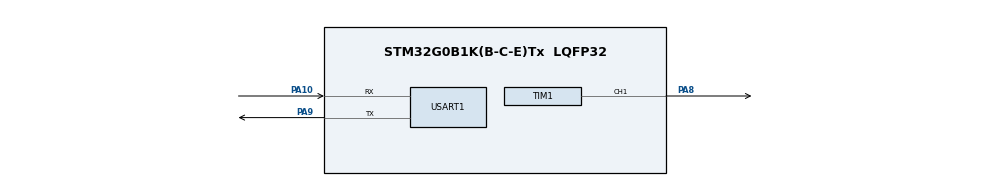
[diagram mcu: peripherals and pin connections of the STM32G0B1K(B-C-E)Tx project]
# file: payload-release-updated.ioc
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Mcu.Family=STM32G0
Mcu.Name=STM32G0B1K(B-C-E)Tx
Mcu.Package=LQFP32
PA10.Mode=Asynchronous
PA10.Signal=USART1_RX
PA8.Signal=S_TIM1_CH1
PA9.Mode=Asynchronous
PA9.Signal=USART1_TX
ProjectManager.HeapSize=0x200
ProjectManager.StackSize=0x400
ProjectManager.TargetToolchain=CMake
RCC.AHBFreq_Value=16000000
RCC.CortexFreq_Value=16000000
RCC.EXTERNAL_CLOCK_VALUE=48000
RCC.HCLKFreq_Value=16000000
RCC.HSE_VALUE=8000000
RCC.HSI48_VALUE=48000000
RCC.HSI_VALUE=16000000
RCC.LSE_VALUE=32768
RCC.SYSCLKFreq_VALUE=16000000
RCC.USBFreq_Value=48000000
RCC.VCOOutputFreq_Value=128000000
SH.S_TIM1_CH1.0=TIM1_CH1,PWM Generation1 CH1
TIM1.Channel-PWM\ Generation1\ CH1=TIM_CHANNEL_1
TIM1.Period=19999
TIM1.Prescaler=15
TIM1.Pulse-PWM\ Generation1\ CH1=1500
USART1.VirtualMode-Asynchronous=VM_ASYNC
VP_SYS_VS_DBSignals.Mode=DisableDeadBatterySignals
VP_TIM1_VS_ClockSourceINT.Mode=Internal
board=custom

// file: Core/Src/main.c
/* USER CODE BEGIN Header */
/**
  ******************************************************************************
  * @file           : main.c
  * @brief          : Main program body
  ******************************************************************************
  * @attention
  *
  * Copyright (c) 2026 STMicroelectronics.
  * All rights reserved.
  *
  * This software is licensed under terms that can be found in the LICENSE file
  * in the root directory of this software component.
  * If no LICENSE file comes with this software, it is provided AS-IS.
  *
  ******************************************************************************
  */
/* USER CODE END Header */
#include <stdint.h>
#include "system_stm32g0xx.h"
#define _GNU_SOURCE
#include "main.h"

/* USER CODE BEGIN Includes */
#include <stdint.h>
#include <stdbool.h>
#include <string.h>
#include <ctype.h>
#include "uart.h"
#include "servo_control.h"
#include <stdio.h>
/* USER CODE END Includes */

/* USER CODE BEGIN PTD */
typedef enum PayloadState {
  LOCKED,
  ARMED,
  RELEASING,
  RETRACTING,
  FAULT,
  INVALID
} PayloadState;
/* USER CODE END PTD */

/* USER CODE BEGIN PD */
#define RELEASE_MS 2000
#define RETRACT_MS 2000
/* USER CODE END PD */

/* USER CODE BEGIN PM */
#define MAX_CMD_LEN 4
/* USER CODE END PM */

/* USER CODE BEGIN PV */
static uint8_t character;
static uint8_t cmd[MAX_CMD_LEN];
static uint8_t idx;
static PayloadState state;
/* USER CODE END PV */

void SystemClock_Config(void);
static void MX_GPIO_Init(void);
static void MX_TIM1_Init(void);
static void MX_USART1_UART_Init(void);
/* USER CODE BEGIN PFP */
extern volatile uint32_t ticks_ms;
/* USER CODE END PFP */

/* USER CODE BEGIN 0 */
void SysTick_Init() {
  SysTick->CTRL = 0; // Disable SysTick
  SysTick->LOAD = (SystemCoreClock / 1000) - 1;  // Set reload for 1-second interval (at 16 MHz)
  SysTick->VAL  = 0; // Clear current value and flag
  // Enable counter, interrupt, and CPU clock
  SysTick->CTRL = SysTick_CTRL_ENABLE_Msk | SysTick_CTRL_TICKINT_Msk | SysTick_CTRL_CLKSOURCE_Msk;
}
/* USER CODE END 0 */

int main(void)
{
  /* USER CODE BEGIN 1 */
  long long rels_start_ms;
  long long retr_start_ms;
  long long rels_time;
  long long retr_time;
  bool rels_started = false;
  bool retr_started = false;
  bool rels_finished = false;
  bool retr_finished = false;
  bool char_ready = false;
  /* USER CODE END 1 */

  /* MCU Configuration--------------------------------------------------------*/

  /* Reset of all peripherals, Initializes the Flash interface and the Systick. */
  LL_APB2_GRP1_EnableClock(LL_APB2_GRP1_PERIPH_SYSCFG);
  LL_APB1_GRP1_EnableClock(LL_APB1_GRP1_PERIPH_PWR);

  /* SysTick_IRQn interrupt configuration */
  NVIC_SetPriority(SysTick_IRQn, 3);

  /** Disable the internal Pull-Up in Dead Battery pins of UCPD peripheral
  */
  LL_SYSCFG_DisableDBATT(LL_SYSCFG_UCPD1_STROBE);

  /* Configure the system clock */
  SystemClock_Config();

  /* USER CODE BEGIN SysInit */
  SysTick_Init();
  /* USER CODE END SysInit */

  /* Initialize all configured peripherals */
  MX_GPIO_Init();
  MX_TIM1_Init();
  MX_USART1_UART_Init();

  /* Infinite loop */
  /* USER CODE BEGIN WHILE */
  while (1)
  {
    // read uart input character
    // if valid character add it to cmd array
    // check if character array is a valid command
    // execute the command via dispatch table
    char_ready = read_character(&character);
    if (char_ready) {
		if (!isalpha(character) || character == 0) {
			char msg[128];
			snprintf(msg, sizeof(msg), "ERR invalid character '%c'\r\n", character);
			write_string((uint8_t*)msg, strlen(msg));
		}
		cmd[idx++] = character;
		if (idx == MAX_CMD_LEN) {
			idx = 0;
			if (!strncmp((const char*)cmd, "LOCK", MAX_CMD_LEN)) {
				state = LOCKED;
				const char *msg = "OK LOCK\r\n";
				write_string((uint8_t*)msg, strlen(msg));
			} else if (!strncmp((const char*)cmd, "ARMD", MAX_CMD_LEN)) {
				if (state == LOCKED) {
					state = ARMED;
					const char *msg = "OK ARMD\r\n";
					write_string((uint8_t*)msg, strlen(msg));
				} else {
					char msg[128];
					snprintf(msg, sizeof(msg), "ERR cannot enter ARMD from %d\r\n", state);
					write_string((uint8_t*)msg, strlen(msg));
				}
			} else if (!strncmp((const char*)cmd, "RELS", MAX_CMD_LEN)) {
				if (state == ARMED) {
					state = RELEASING;
					const char *msg = "OK RELS\r\n";
					write_string((uint8_t*)msg, strlen(msg));
				} else {
					char msg[128];
					snprintf(msg, sizeof(msg), "ERR cannot enter RELS from %d\r\n", state);
					write_string((uint8_t*)msg, strlen(msg));
				}
			}
		}
    }
    switch (state) {
		case LOCKED:
			break;
		case ARMED:
			break;
		case RELEASING:
			// wait release_ms then transition to retract
			rels_time = ticks_ms;
			if (!rels_started) {
				rels_start_ms = ticks_ms;
				rels_started = true;
				rels_finished = false;
				servo_release();
			} else if (rels_time - rels_start_ms > RELEASE_MS) {
				rels_finished = true;
				rels_started = false;
			}
			if (rels_finished) {
				state = RETRACTING;
				rels_start_ms = 0;
				rels_time = 0;
				rels_started = false;
			}
			break;
		case RETRACTING:
			retr_time = ticks_ms;
			if (!retr_started) {
				retr_start_ms = ticks_ms;
				retr_started = true;
				retr_finished = false;
				servo_retract();
			} else if (retr_time - retr_start_ms > RETRACT_MS) {
				retr_finished = true;
				retr_started = false;
			}
			if (retr_finished) {
				state = LOCKED;
				retr_start_ms = 0;
				retr_time = 0;
				retr_started = false;
			}
			break;
		default:
			break;
	}
  }
  /* USER CODE END WHILE */
}

void SystemClock_Config(void)
{
  /* HSI configuration and activation */
  LL_RCC_HSI_Enable();
  while(LL_RCC_HSI_IsReady() != 1)
  {
  }

  /* Set AHB prescaler*/
  LL_RCC_SetAHBPrescaler(LL_RCC_SYSCLK_DIV_1);

  /* Sysclk activation on the HSI */
  LL_RCC_SetSysClkSource(LL_RCC_SYS_CLKSOURCE_HSI);
  while(LL_RCC_GetSysClkSource() != LL_RCC_SYS_CLKSOURCE_STATUS_HSI)
  {
  }

  /* Set APB1 prescaler*/
  LL_RCC_SetAPB1Prescaler(LL_RCC_APB1_DIV_1);
  LL_Init1msTick(16000000);
  /* Update CMSIS variable (which can be updated also through SystemCoreClockUpdate function) */
  LL_SetSystemCoreClock(16000000);
}

static void MX_TIM1_Init(void)
{

  LL_TIM_InitTypeDef TIM_InitStruct = {0};
  LL_TIM_OC_InitTypeDef TIM_OC_InitStruct = {0};
  LL_TIM_BDTR_InitTypeDef TIM_BDTRInitStruct = {0};

  LL_GPIO_InitTypeDef GPIO_InitStruct = {0};

  LL_RCC_SetTIMClockSource(LL_RCC_TIM1_CLKSOURCE_PCLK1);

  /* Peripheral clock enable */
  LL_APB2_GRP1_EnableClock(LL_APB2_GRP1_PERIPH_TIM1);

  TIM_InitStruct.Prescaler = 15;
  TIM_InitStruct.CounterMode = LL_TIM_COUNTERMODE_UP;
  TIM_InitStruct.Autoreload = 19999;
  TIM_InitStruct.ClockDivision = LL_TIM_CLOCKDIVISION_DIV1;
  TIM_InitStruct.RepetitionCounter = 0;
  LL_TIM_Init(TIM1, &TIM_InitStruct);
  LL_TIM_DisableARRPreload(TIM1);
  LL_TIM_SetClockSource(TIM1, LL_TIM_CLOCKSOURCE_INTERNAL);
  LL_TIM_OC_EnablePreload(TIM1, LL_TIM_CHANNEL_CH1);
  TIM_OC_InitStruct.OCMode = LL_TIM_OCMODE_PWM1;
  TIM_OC_InitStruct.OCState = LL_TIM_OCSTATE_DISABLE;
  TIM_OC_InitStruct.OCNState = LL_TIM_OCSTATE_DISABLE;
  TIM_OC_InitStruct.CompareValue = 1500;
  TIM_OC_InitStruct.OCPolarity = LL_TIM_OCPOLARITY_HIGH;
  TIM_OC_InitStruct.OCNPolarity = LL_TIM_OCPOLARITY_HIGH;
  TIM_OC_InitStruct.OCIdleState = LL_TIM_OCIDLESTATE_LOW;
  TIM_OC_InitStruct.OCNIdleState = LL_TIM_OCIDLESTATE_LOW;
  LL_TIM_OC_Init(TIM1, LL_TIM_CHANNEL_CH1, &TIM_OC_InitStruct);
  LL_TIM_OC_DisableFast(TIM1, LL_TIM_CHANNEL_CH1);
  LL_TIM_SetTriggerOutput(TIM1, LL_TIM_TRGO_RESET);
  LL_TIM_SetTriggerOutput2(TIM1, LL_TIM_TRGO2_RESET);
  LL_TIM_DisableMasterSlaveMode(TIM1);
  TIM_BDTRInitStruct.OSSRState = LL_TIM_OSSR_DISABLE;
  TIM_BDTRInitStruct.OSSIState = LL_TIM_OSSI_DISABLE;
  TIM_BDTRInitStruct.LockLevel = LL_TIM_LOCKLEVEL_OFF;
  TIM_BDTRInitStruct.DeadTime = 0;
  TIM_BDTRInitStruct.BreakState = LL_TIM_BREAK_DISABLE;
  TIM_BDTRInitStruct.BreakPolarity = LL_TIM_BREAK_POLARITY_HIGH;
  TIM_BDTRInitStruct.BreakFilter = LL_TIM_BREAK_FILTER_FDIV1;
  TIM_BDTRInitStruct.BreakAFMode = LL_TIM_BREAK_AFMODE_INPUT;
  TIM_BDTRInitStruct.Break2State = LL_TIM_BREAK2_DISABLE;
  TIM_BDTRInitStruct.Break2Polarity = LL_TIM_BREAK2_POLARITY_HIGH;
  TIM_BDTRInitStruct.Break2Filter = LL_TIM_BREAK2_FILTER_FDIV1;
  TIM_BDTRInitStruct.Break2AFMode = LL_TIM_BREAK_AFMODE_INPUT;
  TIM_BDTRInitStruct.AutomaticOutput = LL_TIM_AUTOMATICOUTPUT_DISABLE;
  LL_TIM_BDTR_Init(TIM1, &TIM_BDTRInitStruct);
  LL_IOP_GRP1_EnableClock(LL_IOP_GRP1_PERIPH_GPIOA);
  /**TIM1 GPIO Configuration
  PA8   ------> TIM1_CH1
  */
  GPIO_InitStruct.Pin = LL_GPIO_PIN_8;
  GPIO_InitStruct.Mode = LL_GPIO_MODE_ALTERNATE;
  GPIO_InitStruct.Speed = LL_GPIO_SPEED_FREQ_LOW;
  GPIO_InitStruct.OutputType = LL_GPIO_OUTPUT_PUSHPULL;
  GPIO_InitStruct.Pull = LL_GPIO_PULL_NO;
  GPIO_InitStruct.Alternate = LL_GPIO_AF_2;
  LL_GPIO_Init(GPIOA, &GPIO_InitStruct);

}

static void MX_USART1_UART_Init(void)
{

  LL_USART_InitTypeDef USART_InitStruct = {0};

  LL_GPIO_InitTypeDef GPIO_InitStruct = {0};

  LL_RCC_SetUSARTClockSource(LL_RCC_USART1_CLKSOURCE_PCLK1);

  /* Peripheral clock enable */
  LL_APB2_GRP1_EnableClock(LL_APB2_GRP1_PERIPH_USART1);

  LL_IOP_GRP1_EnableClock(LL_IOP_GRP1_PERIPH_GPIOA);
  /**USART1 GPIO Configuration
  PA9   ------> USART1_TX
  PA10   ------> USART1_RX
  */
  GPIO_InitStruct.Pin = LL_GPIO_PIN_9;
  GPIO_InitStruct.Mode = LL_GPIO_MODE_ALTERNATE;
  GPIO_InitStruct.Speed = LL_GPIO_SPEED_FREQ_LOW;
  GPIO_InitStruct.OutputType = LL_GPIO_OUTPUT_PUSHPULL;
  GPIO_InitStruct.Pull = LL_GPIO_PULL_NO;
  GPIO_InitStruct.Alternate = LL_GPIO_AF_1;
  LL_GPIO_Init(GPIOA, &GPIO_InitStruct);

  GPIO_InitStruct.Pin = LL_GPIO_PIN_10;
  GPIO_InitStruct.Mode = LL_GPIO_MODE_ALTERNATE;
  GPIO_InitStruct.Speed = LL_GPIO_SPEED_FREQ_LOW;
  GPIO_InitStruct.OutputType = LL_GPIO_OUTPUT_PUSHPULL;
  GPIO_InitStruct.Pull = LL_GPIO_PULL_NO;
  GPIO_InitStruct.Alternate = LL_GPIO_AF_1;
  LL_GPIO_Init(GPIOA, &GPIO_InitStruct);

  USART_InitStruct.PrescalerValue = LL_USART_PRESCALER_DIV1;
  USART_InitStruct.BaudRate = 115200;
  USART_InitStruct.DataWidth = LL_USART_DATAWIDTH_8B;
  USART_InitStruct.StopBits = LL_USART_STOPBITS_1;
  USART_InitStruct.Parity = LL_USART_PARITY_NONE;
  USART_InitStruct.TransferDirection = LL_USART_DIRECTION_TX_RX;
  USART_InitStruct.HardwareFlowControl = LL_USART_HWCONTROL_NONE;
  USART_InitStruct.OverSampling = LL_USART_OVERSAMPLING_16;
  LL_USART_Init(USART1, &USART_InitStruct);
  LL_USART_SetTXFIFOThreshold(USART1, LL_USART_FIFOTHRESHOLD_1_8);
  LL_USART_SetRXFIFOThreshold(USART1, LL_USART_FIFOTHRESHOLD_1_8);
  LL_USART_DisableFIFO(USART1);
  LL_USART_ConfigAsyncMode(USART1);

  LL_USART_Enable(USART1);

  /* Polling USART1 initialisation */
  while((!(LL_USART_IsActiveFlag_TEACK(USART1))) || (!(LL_USART_IsActiveFlag_REACK(USART1))))
  {
  }

}

static void MX_GPIO_Init(void)
{

  /* GPIO Ports Clock Enable */
  LL_IOP_GRP1_EnableClock(LL_IOP_GRP1_PERIPH_GPIOA);

}

void Error_Handler(void)
{
  __disable_irq();
  while (1)
  {
  }
}
